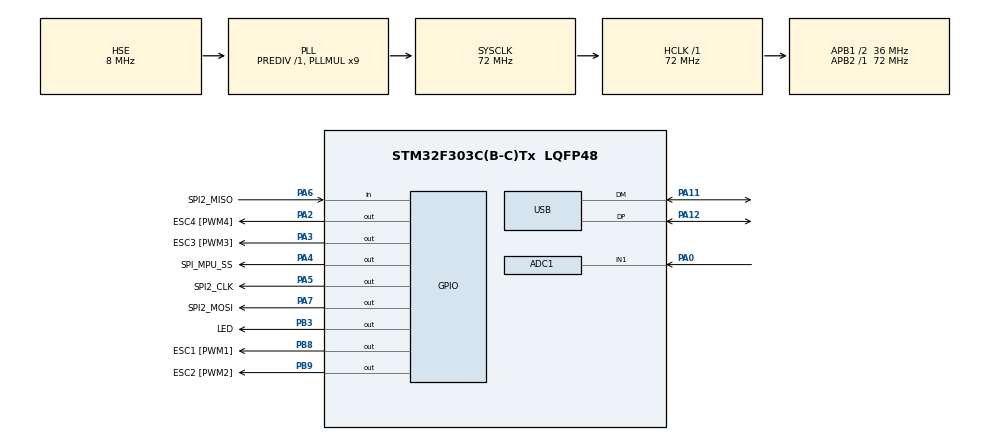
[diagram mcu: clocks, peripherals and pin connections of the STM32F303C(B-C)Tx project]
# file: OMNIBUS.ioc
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ADC1.Channel-0\#ChannelRegularConversion=ADC_CHANNEL_1
ADC1.Channel-1\#ChannelRegularConversion=ADC_CHANNEL_VREFINT
ADC1.ClockPrescaler=ADC_CLOCK_ASYNC_DIV1
ADC1.ContinuousConvMode=ENABLE
ADC1.DMAContinuousRequests=ENABLE
ADC1.NbrOfConversion=2
ADC1.NbrOfConversionFlag=1
ADC1.Offset-0\#ChannelRegularConversion=0
ADC1.Offset-1\#ChannelRegularConversion=0
ADC1.OffsetNumber-0\#ChannelRegularConversion=ADC_OFFSET_NONE
ADC1.OffsetNumber-1\#ChannelRegularConversion=ADC_OFFSET_NONE
ADC1.Rank-0\#ChannelRegularConversion=1
ADC1.Rank-1\#ChannelRegularConversion=2
ADC1.SamplingTime-0\#ChannelRegularConversion=ADC_SAMPLETIME_181CYCLES_5
ADC1.SamplingTime-1\#ChannelRegularConversion=ADC_SAMPLETIME_181CYCLES_5
ADC1.master=1
Dma.ADC1.3.Direction=DMA_PERIPH_TO_MEMORY
Dma.ADC1.3.Instance=DMA1_Channel1
Dma.ADC1.3.MemDataAlignment=DMA_MDATAALIGN_WORD
Dma.ADC1.3.MemInc=DMA_MINC_ENABLE
Dma.ADC1.3.Mode=DMA_CIRCULAR
Dma.ADC1.3.PeriphDataAlignment=DMA_PDATAALIGN_WORD
Dma.ADC1.3.PeriphInc=DMA_PINC_DISABLE
Dma.ADC1.3.Priority=DMA_PRIORITY_LOW
Dma.Request0=TIM1_UP
Dma.Request1=TIM1_CH1
Dma.Request2=TIM1_CH2
Dma.Request3=ADC1
Dma.TIM1_CH1.1.Direction=DMA_MEMORY_TO_PERIPH
Dma.TIM1_CH1.1.Instance=DMA1_Channel2
Dma.TIM1_CH1.1.MemDataAlignment=DMA_MDATAALIGN_WORD
Dma.TIM1_CH1.1.MemInc=DMA_MINC_ENABLE
Dma.TIM1_CH1.1.Mode=DMA_NORMAL
Dma.TIM1_CH1.1.PeriphDataAlignment=DMA_PDATAALIGN_WORD
Dma.TIM1_CH1.1.PeriphInc=DMA_PINC_DISABLE
Dma.TIM1_CH1.1.Priority=DMA_PRIORITY_HIGH
Dma.TIM1_CH2.2.Direction=DMA_MEMORY_TO_PERIPH
Dma.TIM1_CH2.2.Instance=DMA1_Channel3
Dma.TIM1_CH2.2.MemDataAlignment=DMA_MDATAALIGN_WORD
Dma.TIM1_CH2.2.MemInc=DMA_MINC_ENABLE
Dma.TIM1_CH2.2.Mode=DMA_NORMAL
Dma.TIM1_CH2.2.PeriphDataAlignment=DMA_PDATAALIGN_WORD
Dma.TIM1_CH2.2.PeriphInc=DMA_PINC_DISABLE
Dma.TIM1_CH2.2.Priority=DMA_PRIORITY_HIGH
Dma.TIM1_UP.0.Direction=DMA_MEMORY_TO_PERIPH
Dma.TIM1_UP.0.Instance=DMA1_Channel5
Dma.TIM1_UP.0.MemDataAlignment=DMA_MDATAALIGN_WORD
Dma.TIM1_UP.0.MemInc=DMA_MINC_DISABLE
Dma.TIM1_UP.0.Mode=DMA_NORMAL
Dma.TIM1_UP.0.PeriphDataAlignment=DMA_PDATAALIGN_WORD
Dma.TIM1_UP.0.PeriphInc=DMA_PINC_DISABLE
Dma.TIM1_UP.0.Priority=DMA_PRIORITY_HIGH
Mcu.Family=STM32F3
Mcu.Name=STM32F303C(B-C)Tx
Mcu.Package=LQFP48
NVIC.DMA1_Channel1_IRQn=true\:0\:0\:false\:false\:true\:false\:true
NVIC.DMA1_Channel2_IRQn=true\:0\:0\:false\:false\:true\:false\:true
NVIC.DMA1_Channel3_IRQn=true\:0\:0\:false\:false\:false\:false\:false
NVIC.DMA1_Channel5_IRQn=true\:0\:0\:false\:false\:true\:false\:true
NVIC.PriorityGroup=NVIC_PRIORITYGROUP_4
NVIC.USB_LP_CAN_RX0_IRQn=true\:0\:0\:false\:false\:true\:false\:true
PA0.Mode=IN1-Single-Ended
PA0.Signal=ADC1_IN1
PA11.Mode=Device
PA11.Signal=USB_DM
PA12.Mode=Device
PA12.Signal=USB_DP
PA13.Mode=Serial_Wire
PA13.Signal=SYS_JTMS-SWDIO
PA14.Mode=Serial_Wire
PA14.Signal=SYS_JTCK-SWCLK
PA2.GPIO_Label=ESC4 [PWM4]
PA2.GPIO_Speed=GPIO_SPEED_FREQ_HIGH
PA2.Signal=GPIO_Output
PA3.GPIO_Label=ESC3 [PWM3]
PA3.GPIO_Speed=GPIO_SPEED_FREQ_HIGH
PA3.Signal=GPIO_Output
PA4.GPIO_Label=SPI_MPU_SS
PA4.GPIO_Speed=GPIO_SPEED_FREQ_HIGH
PA4.Signal=GPIO_Output
PA5.GPIO_Label=SPI2_CLK
PA5.GPIO_Speed=GPIO_SPEED_FREQ_HIGH
PA5.Signal=GPIO_Output
PA6.GPIO_Label=SPI2_MISO
PA6.Signal=GPIO_Input
PA7.GPIO_Label=SPI2_MOSI
PA7.GPIO_Speed=GPIO_SPEED_FREQ_HIGH
PA7.Signal=GPIO_Output
PB3.GPIO_Label=LED
PB3.GPIO_Speed=GPIO_SPEED_FREQ_HIGH
PB3.PinState=GPIO_PIN_RESET
PB3.Signal=GPIO_Output
PB8.GPIO_Label=ESC1 [PWM1]
PB8.GPIO_Speed=GPIO_SPEED_FREQ_HIGH
PB8.Signal=GPIO_Output
PB9.GPIO_Label=ESC2 [PWM2]
PB9.GPIO_Speed=GPIO_SPEED_FREQ_HIGH
PB9.Signal=GPIO_Output
PF0-OSC_IN.Mode=HSE-External-Oscillator
PF0-OSC_IN.Signal=RCC_OSC_IN
PF1-OSC_OUT.Mode=HSE-External-Oscillator
PF1-OSC_OUT.Signal=RCC_OSC_OUT
ProjectManager.HeapSize=0x200
ProjectManager.StackSize=0x400
ProjectManager.TargetToolchain=MDK-ARM V5
RCC.AHBFreq_Value=72000000
RCC.APB1CLKDivider=RCC_HCLK_DIV2
RCC.APB1Freq_Value=36000000
RCC.APB1TimFreq_Value=72000000
RCC.APB2Freq_Value=72000000
RCC.APB2TimFreq_Value=72000000
RCC.CortexFreq_Value=72000000
RCC.HCLKFreq_Value=72000000
RCC.HSE_VALUE=8000000
RCC.HSI_VALUE=8000000
RCC.LSE_VALUE=32768
RCC.PLLMUL=RCC_PLL_MUL9
RCC.PRESCALERUSB=RCC_USBCLKSOURCE_PLL_DIV1_5
RCC.SYSCLKFreq_VALUE=72000000
RCC.SYSCLKSourceVirtual=RCC_SYSCLKSOURCE_PLLCLK
RCC.USBFreq_Value=48000000
TIM1.Channel-Output\ Compare1\ No\ Output=TIM_CHANNEL_1
TIM1.Channel-Output\ Compare2\ No\ Output=TIM_CHANNEL_2
TIM2.Period=0xFFFFFFFF
TIM2.Prescaler=72
USB_DEVICE.CLASS_NAME_FS=CDC
USB_DEVICE.VirtualMode=Cdc
USB_DEVICE.VirtualModeFS=Cdc_FS
VP_ADC1_Vref_Input.Mode=IN-Vrefint
VP_TIM1_VS_ClockSourceINT.Mode=Internal
VP_TIM1_VS_no_output1.Mode=Output Compare1 No Output
VP_TIM1_VS_no_output2.Mode=Output Compare2 No Output
VP_TIM2_VS_ClockSourceINT.Mode=Internal
VP_USB_DEVICE_VS_USB_DEVICE_CDC_FS.Mode=CDC_FS
board=custom

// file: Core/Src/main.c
/* USER CODE BEGIN Header */
/**
  ******************************************************************************
  * @file           : main.c
  * @brief          : Main program body
  ******************************************************************************
  * @attention
  *
  * <h2><center>&copy; Copyright (c) 2020 STMicroelectronics.
  * All rights reserved.</center></h2>
  *
  * This software component is licensed by ST under BSD 3-Clause license,
  * the "License"; You may not use this file except in compliance with the
  * License. You may obtain a copy of the License at:
  *                        opensource.org/licenses/BSD-3-Clause
  *
  ******************************************************************************
  */
/* USER CODE END Header */

#include "main.h"
#include "usb_device.h"

ADC_HandleTypeDef hadc1;
DMA_HandleTypeDef hdma_adc1;

TIM_HandleTypeDef htim1;
TIM_HandleTypeDef htim2;
DMA_HandleTypeDef hdma_tim1_up;
DMA_HandleTypeDef hdma_tim1_ch1;
DMA_HandleTypeDef hdma_tim1_ch2;

void SystemClock_Config(void);
static void MX_GPIO_Init(void);
static void MX_DMA_Init(void);
static void MX_ADC1_Init(void);
static void MX_TIM1_Init(void);
static void MX_TIM2_Init(void);

int main(void)
{

  /* MCU Configuration--------------------------------------------------------*/

  /* Reset of all peripherals, Initializes the Flash interface and the Systick. */
  HAL_Init();

  /* Configure the system clock */
  SystemClock_Config();

  /* Initialize all configured peripherals */
  MX_GPIO_Init();
  MX_DMA_Init();
  MX_ADC1_Init();
  MX_TIM1_Init();
  MX_TIM2_Init();
  MX_USB_DEVICE_Init();

  /* Infinite loop */
  /* USER CODE BEGIN WHILE */
extern void usermain();
usermain();
  while (1)
  {
    /* USER CODE END WHILE */

  }
}

void SystemClock_Config(void)
{
  RCC_OscInitTypeDef RCC_OscInitStruct = {0};
  RCC_ClkInitTypeDef RCC_ClkInitStruct = {0};
  RCC_PeriphCLKInitTypeDef PeriphClkInit = {0};

  /** Initializes the CPU, AHB and APB busses clocks
  */
  RCC_OscInitStruct.OscillatorType = RCC_OSCILLATORTYPE_HSE;
  RCC_OscInitStruct.HSEState = RCC_HSE_ON;
  RCC_OscInitStruct.HSEPredivValue = RCC_HSE_PREDIV_DIV1;
  RCC_OscInitStruct.HSIState = RCC_HSI_ON;
  RCC_OscInitStruct.PLL.PLLState = RCC_PLL_ON;
  RCC_OscInitStruct.PLL.PLLSource = RCC_PLLSOURCE_HSE;
  RCC_OscInitStruct.PLL.PLLMUL = RCC_PLL_MUL9;
  if (HAL_RCC_OscConfig(&RCC_OscInitStruct) != HAL_OK)
  {
    Error_Handler();
  }
  /** Initializes the CPU, AHB and APB busses clocks
  */
  RCC_ClkInitStruct.ClockType = RCC_CLOCKTYPE_HCLK|RCC_CLOCKTYPE_SYSCLK
                              |RCC_CLOCKTYPE_PCLK1|RCC_CLOCKTYPE_PCLK2;
  RCC_ClkInitStruct.SYSCLKSource = RCC_SYSCLKSOURCE_PLLCLK;
  RCC_ClkInitStruct.AHBCLKDivider = RCC_SYSCLK_DIV1;
  RCC_ClkInitStruct.APB1CLKDivider = RCC_HCLK_DIV2;
  RCC_ClkInitStruct.APB2CLKDivider = RCC_HCLK_DIV1;

  if (HAL_RCC_ClockConfig(&RCC_ClkInitStruct, FLASH_LATENCY_2) != HAL_OK)
  {
    Error_Handler();
  }
  PeriphClkInit.PeriphClockSelection = RCC_PERIPHCLK_USB|RCC_PERIPHCLK_TIM1
                              |RCC_PERIPHCLK_ADC12;
  PeriphClkInit.Adc12ClockSelection = RCC_ADC12PLLCLK_DIV1;
  PeriphClkInit.USBClockSelection = RCC_USBCLKSOURCE_PLL_DIV1_5;
  PeriphClkInit.Tim1ClockSelection = RCC_TIM1CLK_HCLK;
  if (HAL_RCCEx_PeriphCLKConfig(&PeriphClkInit) != HAL_OK)
  {
    Error_Handler();
  }
}

static void MX_ADC1_Init(void)
{

  ADC_MultiModeTypeDef multimode = {0};
  ADC_ChannelConfTypeDef sConfig = {0};

  /** Common config
  */
  hadc1.Instance = ADC1;
  hadc1.Init.ClockPrescaler = ADC_CLOCK_ASYNC_DIV1;
  hadc1.Init.Resolution = ADC_RESOLUTION_12B;
  hadc1.Init.ScanConvMode = ADC_SCAN_ENABLE;
  hadc1.Init.ContinuousConvMode = ENABLE;
  hadc1.Init.DiscontinuousConvMode = DISABLE;
  hadc1.Init.ExternalTrigConvEdge = ADC_EXTERNALTRIGCONVEDGE_NONE;
  hadc1.Init.ExternalTrigConv = ADC_SOFTWARE_START;
  hadc1.Init.DataAlign = ADC_DATAALIGN_RIGHT;
  hadc1.Init.NbrOfConversion = 2;
  hadc1.Init.DMAContinuousRequests = ENABLE;
  hadc1.Init.EOCSelection = ADC_EOC_SINGLE_CONV;
  hadc1.Init.LowPowerAutoWait = DISABLE;
  hadc1.Init.Overrun = ADC_OVR_DATA_OVERWRITTEN;
  if (HAL_ADC_Init(&hadc1) != HAL_OK)
  {
    Error_Handler();
  }
  /** Configure the ADC multi-mode
  */
  multimode.Mode = ADC_MODE_INDEPENDENT;
  if (HAL_ADCEx_MultiModeConfigChannel(&hadc1, &multimode) != HAL_OK)
  {
    Error_Handler();
  }
  /** Configure Regular Channel
  */
  sConfig.Channel = ADC_CHANNEL_1;
  sConfig.Rank = ADC_REGULAR_RANK_1;
  sConfig.SingleDiff = ADC_SINGLE_ENDED;
  sConfig.SamplingTime = ADC_SAMPLETIME_181CYCLES_5;
  sConfig.OffsetNumber = ADC_OFFSET_NONE;
  sConfig.Offset = 0;
  if (HAL_ADC_ConfigChannel(&hadc1, &sConfig) != HAL_OK)
  {
    Error_Handler();
  }
  /** Configure Regular Channel
  */
  sConfig.Channel = ADC_CHANNEL_VREFINT;
  sConfig.Rank = ADC_REGULAR_RANK_2;
  if (HAL_ADC_ConfigChannel(&hadc1, &sConfig) != HAL_OK)
  {
    Error_Handler();
  }

}

static void MX_TIM1_Init(void)
{

  TIM_ClockConfigTypeDef sClockSourceConfig = {0};
  TIM_MasterConfigTypeDef sMasterConfig = {0};
  TIM_OC_InitTypeDef sConfigOC = {0};
  TIM_BreakDeadTimeConfigTypeDef sBreakDeadTimeConfig = {0};

  htim1.Instance = TIM1;
  htim1.Init.Prescaler = 0;
  htim1.Init.CounterMode = TIM_COUNTERMODE_UP;
  htim1.Init.Period = 0;
  htim1.Init.ClockDivision = TIM_CLOCKDIVISION_DIV1;
  htim1.Init.RepetitionCounter = 0;
  htim1.Init.AutoReloadPreload = TIM_AUTORELOAD_PRELOAD_DISABLE;
  if (HAL_TIM_Base_Init(&htim1) != HAL_OK)
  {
    Error_Handler();
  }
  sClockSourceConfig.ClockSource = TIM_CLOCKSOURCE_INTERNAL;
  if (HAL_TIM_ConfigClockSource(&htim1, &sClockSourceConfig) != HAL_OK)
  {
    Error_Handler();
  }
  if (HAL_TIM_OC_Init(&htim1) != HAL_OK)
  {
    Error_Handler();
  }
  sMasterConfig.MasterOutputTrigger = TIM_TRGO_RESET;
  sMasterConfig.MasterOutputTrigger2 = TIM_TRGO2_RESET;
  sMasterConfig.MasterSlaveMode = TIM_MASTERSLAVEMODE_DISABLE;
  if (HAL_TIMEx_MasterConfigSynchronization(&htim1, &sMasterConfig) != HAL_OK)
  {
    Error_Handler();
  }
  sConfigOC.OCMode = TIM_OCMODE_TIMING;
  sConfigOC.Pulse = 0;
  sConfigOC.OCPolarity = TIM_OCPOLARITY_HIGH;
  sConfigOC.OCNPolarity = TIM_OCNPOLARITY_HIGH;
  sConfigOC.OCFastMode = TIM_OCFAST_DISABLE;
  sConfigOC.OCIdleState = TIM_OCIDLESTATE_RESET;
  sConfigOC.OCNIdleState = TIM_OCNIDLESTATE_RESET;
  if (HAL_TIM_OC_ConfigChannel(&htim1, &sConfigOC, TIM_CHANNEL_1) != HAL_OK)
  {
    Error_Handler();
  }
  if (HAL_TIM_OC_ConfigChannel(&htim1, &sConfigOC, TIM_CHANNEL_2) != HAL_OK)
  {
    Error_Handler();
  }
  sBreakDeadTimeConfig.OffStateRunMode = TIM_OSSR_DISABLE;
  sBreakDeadTimeConfig.OffStateIDLEMode = TIM_OSSI_DISABLE;
  sBreakDeadTimeConfig.LockLevel = TIM_LOCKLEVEL_OFF;
  sBreakDeadTimeConfig.DeadTime = 0;
  sBreakDeadTimeConfig.BreakState = TIM_BREAK_DISABLE;
  sBreakDeadTimeConfig.BreakPolarity = TIM_BREAKPOLARITY_HIGH;
  sBreakDeadTimeConfig.BreakFilter = 0;
  sBreakDeadTimeConfig.Break2State = TIM_BREAK2_DISABLE;
  sBreakDeadTimeConfig.Break2Polarity = TIM_BREAK2POLARITY_HIGH;
  sBreakDeadTimeConfig.Break2Filter = 0;
  sBreakDeadTimeConfig.AutomaticOutput = TIM_AUTOMATICOUTPUT_DISABLE;
  if (HAL_TIMEx_ConfigBreakDeadTime(&htim1, &sBreakDeadTimeConfig) != HAL_OK)
  {
    Error_Handler();
  }

}

static void MX_TIM2_Init(void)
{

  TIM_ClockConfigTypeDef sClockSourceConfig = {0};
  TIM_MasterConfigTypeDef sMasterConfig = {0};

  htim2.Instance = TIM2;
  htim2.Init.Prescaler = 72;
  htim2.Init.CounterMode = TIM_COUNTERMODE_UP;
  htim2.Init.Period = 0xFFFFFFFF;
  htim2.Init.ClockDivision = TIM_CLOCKDIVISION_DIV1;
  htim2.Init.AutoReloadPreload = TIM_AUTORELOAD_PRELOAD_DISABLE;
  if (HAL_TIM_Base_Init(&htim2) != HAL_OK)
  {
    Error_Handler();
  }
  sClockSourceConfig.ClockSource = TIM_CLOCKSOURCE_INTERNAL;
  if (HAL_TIM_ConfigClockSource(&htim2, &sClockSourceConfig) != HAL_OK)
  {
    Error_Handler();
  }
  sMasterConfig.MasterOutputTrigger = TIM_TRGO_RESET;
  sMasterConfig.MasterSlaveMode = TIM_MASTERSLAVEMODE_DISABLE;
  if (HAL_TIMEx_MasterConfigSynchronization(&htim2, &sMasterConfig) != HAL_OK)
  {
    Error_Handler();
  }

}

static void MX_DMA_Init(void)
{

  /* DMA controller clock enable */
  __HAL_RCC_DMA1_CLK_ENABLE();

  /* DMA interrupt init */
  /* DMA1_Channel1_IRQn interrupt configuration */
  HAL_NVIC_SetPriority(DMA1_Channel1_IRQn, 0, 0);
  HAL_NVIC_EnableIRQ(DMA1_Channel1_IRQn);
  /* DMA1_Channel2_IRQn interrupt configuration */
  HAL_NVIC_SetPriority(DMA1_Channel2_IRQn, 0, 0);
  HAL_NVIC_EnableIRQ(DMA1_Channel2_IRQn);
  /* DMA1_Channel3_IRQn interrupt configuration */
  HAL_NVIC_SetPriority(DMA1_Channel3_IRQn, 0, 0);
  HAL_NVIC_EnableIRQ(DMA1_Channel3_IRQn);
  /* DMA1_Channel5_IRQn interrupt configuration */
  HAL_NVIC_SetPriority(DMA1_Channel5_IRQn, 0, 0);
  HAL_NVIC_EnableIRQ(DMA1_Channel5_IRQn);

}

static void MX_GPIO_Init(void)
{
  GPIO_InitTypeDef GPIO_InitStruct = {0};

  /* GPIO Ports Clock Enable */
  __HAL_RCC_GPIOF_CLK_ENABLE();
  __HAL_RCC_GPIOA_CLK_ENABLE();
  __HAL_RCC_GPIOB_CLK_ENABLE();

  /*Configure GPIO pin Output Level */
  HAL_GPIO_WritePin(GPIOA, ESC4_Pin|ESC3_Pin|SPI_MPU_SS_Pin|SPI2_CLK_Pin
                          |SPI2_MOSI_Pin, GPIO_PIN_RESET);

  /*Configure GPIO pin Output Level */
  HAL_GPIO_WritePin(GPIOB, LED_Pin|ESC1_Pin|ESC2_Pin, GPIO_PIN_RESET);

  /*Configure GPIO pins : ESC4_Pin ESC3_Pin SPI_MPU_SS_Pin SPI2_CLK_Pin
                           SPI2_MOSI_Pin */
  GPIO_InitStruct.Pin = ESC4_Pin|ESC3_Pin|SPI_MPU_SS_Pin|SPI2_CLK_Pin
                          |SPI2_MOSI_Pin;
  GPIO_InitStruct.Mode = GPIO_MODE_OUTPUT_PP;
  GPIO_InitStruct.Pull = GPIO_NOPULL;
  GPIO_InitStruct.Speed = GPIO_SPEED_FREQ_HIGH;
  HAL_GPIO_Init(GPIOA, &GPIO_InitStruct);

  /*Configure GPIO pin : SPI2_MISO_Pin */
  GPIO_InitStruct.Pin = SPI2_MISO_Pin;
  GPIO_InitStruct.Mode = GPIO_MODE_INPUT;
  GPIO_InitStruct.Pull = GPIO_NOPULL;
  HAL_GPIO_Init(SPI2_MISO_GPIO_Port, &GPIO_InitStruct);

  /*Configure GPIO pins : LED_Pin ESC1_Pin ESC2_Pin */
  GPIO_InitStruct.Pin = LED_Pin|ESC1_Pin|ESC2_Pin;
  GPIO_InitStruct.Mode = GPIO_MODE_OUTPUT_PP;
  GPIO_InitStruct.Pull = GPIO_NOPULL;
  GPIO_InitStruct.Speed = GPIO_SPEED_FREQ_HIGH;
  HAL_GPIO_Init(GPIOB, &GPIO_InitStruct);

}

void Error_Handler(void)
{
}

/************************ (C) COPYRIGHT STMicroelectronics *****END OF FILE****/
